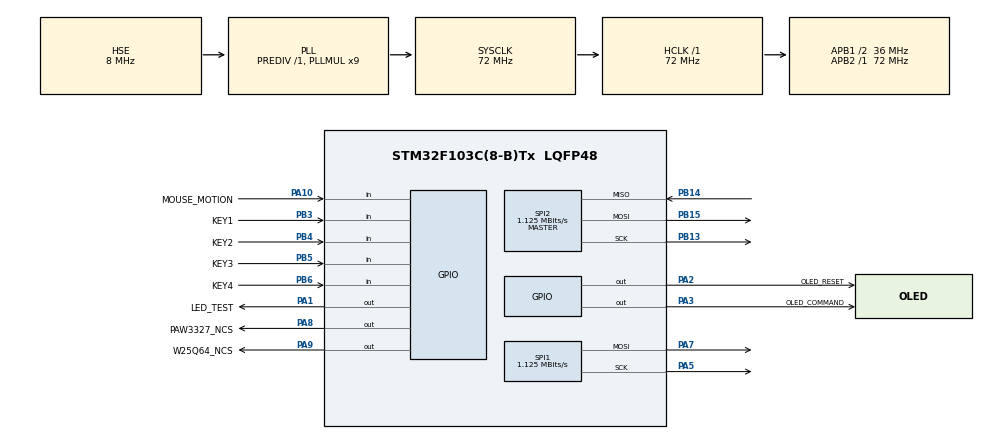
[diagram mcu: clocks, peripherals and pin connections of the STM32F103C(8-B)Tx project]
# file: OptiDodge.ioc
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Mcu.Family=STM32F1
Mcu.Name=STM32F103C(8-B)Tx
Mcu.Package=LQFP48
NVIC.PriorityGroup=NVIC_PRIORITYGROUP_4
NVIC.TIM2_IRQn=true\:1\:0\:true\:false\:true\:false\:true\:true
NVIC.TimeBase=TIM2_IRQn
NVIC.TimeBaseIP=TIM2
PA1.GPIO_Label=LED_TEST
PA1.GPIO_PuPd=GPIO_PULLUP
PA1.Signal=GPIO_Output
PA10.GPIO_Label=MOUSE_MOTION
PA10.Signal=GPIO_Input
PA13.Mode=Serial_Wire
PA13.Signal=SYS_JTMS-SWDIO
PA14.Mode=Serial_Wire
PA14.Signal=SYS_JTCK-SWCLK
PA2.GPIO_Label=OLED_RESET
PA2.Signal=GPIO_Output
PA3.GPIO_Label=OLED_COMMAND
PA3.Signal=GPIO_Output
PA5.Mode=TX_Only_Simplex_Unidirect_Master
PA5.Signal=SPI1_SCK
PA7.Mode=TX_Only_Simplex_Unidirect_Master
PA7.Signal=SPI1_MOSI
PA8.GPIO_Label=PAW3327_NCS
PA8.PinState=GPIO_PIN_SET
PA8.Signal=GPIO_Output
PA9.GPIO_Label=W25Q64_NCS
PA9.PinState=GPIO_PIN_SET
PA9.Signal=GPIO_Output
PB13.Mode=Full_Duplex_Master
PB13.Signal=SPI2_SCK
PB14.Mode=Full_Duplex_Master
PB14.Signal=SPI2_MISO
PB15.Mode=Full_Duplex_Master
PB15.Signal=SPI2_MOSI
PB3.GPIO_Label=KEY1
PB3.GPIO_PuPd=GPIO_PULLUP
PB3.Signal=GPIO_Input
PB4.GPIO_Label=KEY2
PB4.GPIO_PuPd=GPIO_PULLUP
PB4.Signal=GPIO_Input
PB5.GPIO_Label=KEY3
PB5.GPIO_PuPd=GPIO_PULLUP
PB5.Signal=GPIO_Input
PB6.GPIO_Label=KEY4
PB6.GPIO_PuPd=GPIO_PULLUP
PB6.Signal=GPIO_Input
PD0-OSC_IN.Mode=HSE-External-Oscillator
PD0-OSC_IN.Signal=RCC_OSC_IN
PD1-OSC_OUT.Mode=HSE-External-Oscillator
PD1-OSC_OUT.Signal=RCC_OSC_OUT
ProjectManager.HeapSize=0x200
ProjectManager.StackSize=0x400
ProjectManager.TargetToolchain=MDK-ARM V5
RCC.AHBFreq_Value=72000000
RCC.APB1CLKDivider=RCC_HCLK_DIV2
RCC.APB1Freq_Value=36000000
RCC.APB1TimFreq_Value=72000000
RCC.APB2Freq_Value=72000000
RCC.APB2TimFreq_Value=72000000
RCC.HCLKFreq_Value=72000000
RCC.PLLMUL=RCC_PLL_MUL9
RCC.PLLSourceVirtual=RCC_PLLSOURCE_HSE
RCC.SYSCLKFreq_VALUE=72000000
RCC.SYSCLKSource=RCC_SYSCLKSOURCE_PLLCLK
RCC.USBFreq_Value=72000000
SPI1.BaudRatePrescaler=SPI_BAUDRATEPRESCALER_64
SPI1.CLKPhase=SPI_PHASE_2EDGE
SPI1.CLKPolarity=SPI_POLARITY_HIGH
SPI1.CalculateBaudRate=1.125 MBits/s
SPI1.Direction=SPI_DIRECTION_2LINES
SPI1.Mode=SPI_MODE_MASTER
SPI1.VirtualType=VM_MASTER
SPI2.BaudRatePrescaler=SPI_BAUDRATEPRESCALER_32
SPI2.CLKPhase=SPI_PHASE_2EDGE
SPI2.CLKPolarity=SPI_POLARITY_HIGH
SPI2.CalculateBaudRate=1.125 MBits/s
SPI2.Direction=SPI_DIRECTION_2LINES
SPI2.Mode=SPI_MODE_MASTER
SPI2.VirtualType=VM_MASTER
VP_SYS_VS_tim2.Mode=TIM2
board=custom

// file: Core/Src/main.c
/* USER CODE BEGIN Header */
/**
  ******************************************************************************
  * @file           : main.c
  * @brief          : Main program body
  ******************************************************************************
  * @attention
  *
  * Copyright (c) 2026 STMicroelectronics.
  * All rights reserved.
  *
  * This software is licensed under terms that can be found in the LICENSE file
  * in the root directory of this software component.
  * If no LICENSE file comes with this software, it is provided AS-IS.
  *
  ******************************************************************************
  */
/* USER CODE END Header */
#include "main.h"

/* USER CODE BEGIN Includes */
#include <string.h>
#include <stdio.h>
#include "oled.h"
#include "Draw.h"
#include "PAW3327.h"
#include "FreeRTOS_Program.h"
/* USER CODE END Includes */

SPI_HandleTypeDef hspi1;
SPI_HandleTypeDef hspi2;

void SystemClock_Config(void);
static void MX_GPIO_Init(void);
static void MX_SPI1_Init(void);
static void MX_SPI2_Init(void);

int main(void)
{

  /* MCU Configuration--------------------------------------------------------*/

  /* Reset of all peripherals, Initializes the Flash interface and the Systick. */
  HAL_Init();

  /* Configure the system clock */
  SystemClock_Config();

  /* Initialize all configured peripherals */
  MX_GPIO_Init();
  MX_SPI1_Init();
  MX_SPI2_Init();
  /* USER CODE BEGIN 2 */
	/* 先让 OLED 保持复位 */
OLED_RST_Clr();

/* 提前开启 SPI，让时钟先稳定在空闲高电平 */
__HAL_SPI_ENABLE(&hspi1);

/* 再执行完整复位和初始化 */

  OLED_Init();
  OLED_WR_Byte(0xA4, OLED_CMD);  // 恢复显示显存内容
  Set_Font_size(SMALL);
  PAW3327_Init();
  RTOS_Init();
  /* USER CODE END 2 */

  /* Infinite loop */
  while (1)
  {

  }
}

void SystemClock_Config(void)
{
  RCC_OscInitTypeDef RCC_OscInitStruct = {0};
  RCC_ClkInitTypeDef RCC_ClkInitStruct = {0};

  /** Initializes the RCC Oscillators according to the specified parameters
  * in the RCC_OscInitTypeDef structure.
  */
  RCC_OscInitStruct.OscillatorType = RCC_OSCILLATORTYPE_HSE;
  RCC_OscInitStruct.HSEState = RCC_HSE_ON;
  RCC_OscInitStruct.HSEPredivValue = RCC_HSE_PREDIV_DIV1;
  RCC_OscInitStruct.HSIState = RCC_HSI_ON;
  RCC_OscInitStruct.PLL.PLLState = RCC_PLL_ON;
  RCC_OscInitStruct.PLL.PLLSource = RCC_PLLSOURCE_HSE;
  RCC_OscInitStruct.PLL.PLLMUL = RCC_PLL_MUL9;
  if (HAL_RCC_OscConfig(&RCC_OscInitStruct) != HAL_OK)
  {
    Error_Handler();
  }

  /** Initializes the CPU, AHB and APB buses clocks
  */
  RCC_ClkInitStruct.ClockType = RCC_CLOCKTYPE_HCLK|RCC_CLOCKTYPE_SYSCLK
                              |RCC_CLOCKTYPE_PCLK1|RCC_CLOCKTYPE_PCLK2;
  RCC_ClkInitStruct.SYSCLKSource = RCC_SYSCLKSOURCE_PLLCLK;
  RCC_ClkInitStruct.AHBCLKDivider = RCC_SYSCLK_DIV1;
  RCC_ClkInitStruct.APB1CLKDivider = RCC_HCLK_DIV2;
  RCC_ClkInitStruct.APB2CLKDivider = RCC_HCLK_DIV1;

  if (HAL_RCC_ClockConfig(&RCC_ClkInitStruct, FLASH_LATENCY_2) != HAL_OK)
  {
    Error_Handler();
  }
}

static void MX_SPI1_Init(void)
{

  /* SPI1 parameter configuration*/
  hspi1.Instance = SPI1;
  hspi1.Init.Mode = SPI_MODE_MASTER;
  hspi1.Init.Direction = SPI_DIRECTION_2LINES;
  hspi1.Init.DataSize = SPI_DATASIZE_8BIT;
  hspi1.Init.CLKPolarity = SPI_POLARITY_HIGH;
  hspi1.Init.CLKPhase = SPI_PHASE_2EDGE;
  hspi1.Init.NSS = SPI_NSS_SOFT;
  hspi1.Init.BaudRatePrescaler = SPI_BAUDRATEPRESCALER_64;
  hspi1.Init.FirstBit = SPI_FIRSTBIT_MSB;
  hspi1.Init.TIMode = SPI_TIMODE_DISABLE;
  hspi1.Init.CRCCalculation = SPI_CRCCALCULATION_DISABLE;
  hspi1.Init.CRCPolynomial = 10;
  if (HAL_SPI_Init(&hspi1) != HAL_OK)
  {
    Error_Handler();
  }

}

static void MX_SPI2_Init(void)
{

  /* SPI2 parameter configuration*/
  hspi2.Instance = SPI2;
  hspi2.Init.Mode = SPI_MODE_MASTER;
  hspi2.Init.Direction = SPI_DIRECTION_2LINES;
  hspi2.Init.DataSize = SPI_DATASIZE_8BIT;
  hspi2.Init.CLKPolarity = SPI_POLARITY_HIGH;
  hspi2.Init.CLKPhase = SPI_PHASE_2EDGE;
  hspi2.Init.NSS = SPI_NSS_SOFT;
  hspi2.Init.BaudRatePrescaler = SPI_BAUDRATEPRESCALER_32;
  hspi2.Init.FirstBit = SPI_FIRSTBIT_MSB;
  hspi2.Init.TIMode = SPI_TIMODE_DISABLE;
  hspi2.Init.CRCCalculation = SPI_CRCCALCULATION_DISABLE;
  hspi2.Init.CRCPolynomial = 10;
  if (HAL_SPI_Init(&hspi2) != HAL_OK)
  {
    Error_Handler();
  }

}

static void MX_GPIO_Init(void)
{
  GPIO_InitTypeDef GPIO_InitStruct = {0};

  /* GPIO Ports Clock Enable */
  __HAL_RCC_GPIOD_CLK_ENABLE();
  __HAL_RCC_GPIOA_CLK_ENABLE();
  __HAL_RCC_GPIOB_CLK_ENABLE();

  /*Configure GPIO pin Output Level */
  HAL_GPIO_WritePin(GPIOA, LED_TEST_Pin|OLED_RESET_Pin|OLED_COMMAND_Pin, GPIO_PIN_RESET);

  /*Configure GPIO pin Output Level */
  HAL_GPIO_WritePin(GPIOA, PAW3327_NCS_Pin|W25Q64_NCS_Pin, GPIO_PIN_SET);

  /*Configure GPIO pin : LED_TEST_Pin */
  GPIO_InitStruct.Pin = LED_TEST_Pin;
  GPIO_InitStruct.Mode = GPIO_MODE_OUTPUT_PP;
  GPIO_InitStruct.Pull = GPIO_PULLUP;
  GPIO_InitStruct.Speed = GPIO_SPEED_FREQ_LOW;
  HAL_GPIO_Init(LED_TEST_GPIO_Port, &GPIO_InitStruct);

  /*Configure GPIO pins : OLED_RESET_Pin OLED_COMMAND_Pin PAW3327_NCS_Pin W25Q64_NCS_Pin */
  GPIO_InitStruct.Pin = OLED_RESET_Pin|OLED_COMMAND_Pin|PAW3327_NCS_Pin|W25Q64_NCS_Pin;
  GPIO_InitStruct.Mode = GPIO_MODE_OUTPUT_PP;
  GPIO_InitStruct.Pull = GPIO_NOPULL;
  GPIO_InitStruct.Speed = GPIO_SPEED_FREQ_LOW;
  HAL_GPIO_Init(GPIOA, &GPIO_InitStruct);

  /*Configure GPIO pin : MOUSE_MOTION_Pin */
  GPIO_InitStruct.Pin = MOUSE_MOTION_Pin;
  GPIO_InitStruct.Mode = GPIO_MODE_INPUT;
  GPIO_InitStruct.Pull = GPIO_NOPULL;
  HAL_GPIO_Init(MOUSE_MOTION_GPIO_Port, &GPIO_InitStruct);

  /*Configure GPIO pins : KEY1_Pin KEY2_Pin KEY3_Pin KEY4_Pin */
  GPIO_InitStruct.Pin = KEY1_Pin|KEY2_Pin|KEY3_Pin|KEY4_Pin;
  GPIO_InitStruct.Mode = GPIO_MODE_INPUT;
  GPIO_InitStruct.Pull = GPIO_PULLUP;
  HAL_GPIO_Init(GPIOB, &GPIO_InitStruct);

}

void HAL_TIM_PeriodElapsedCallback(TIM_HandleTypeDef *htim)
{
  if (htim->Instance == TIM2)
  {
    HAL_IncTick();
  }
}

void Error_Handler(void)
{
  __disable_irq();
  while (1)
  {
  }
}
